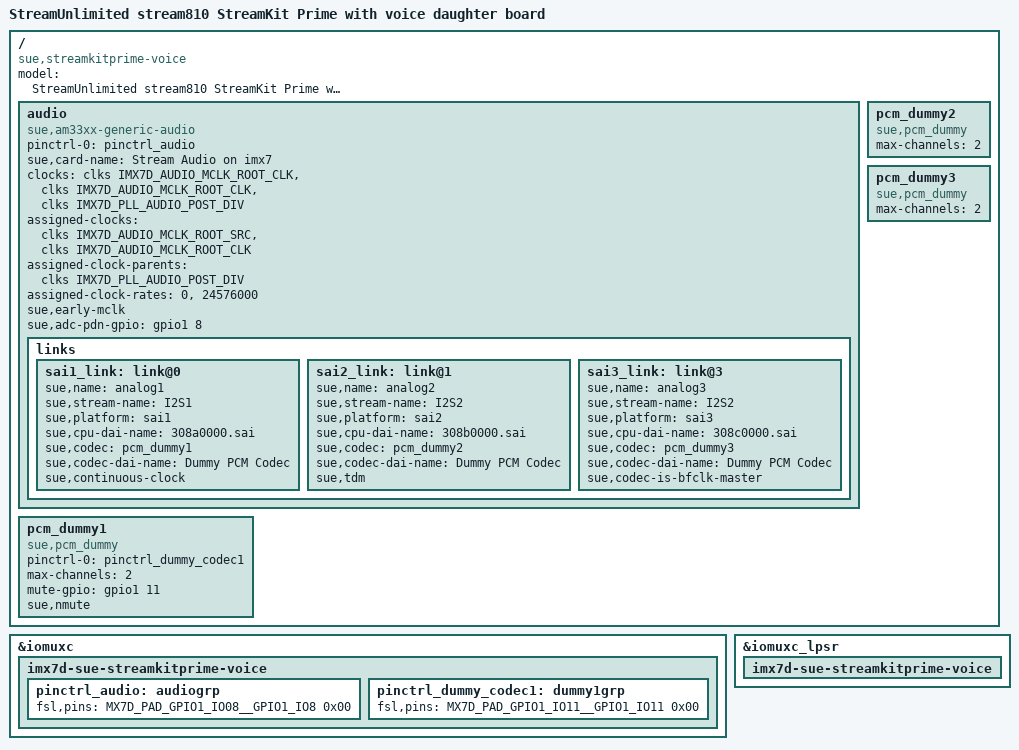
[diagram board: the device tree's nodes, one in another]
/*
 * This program is free software; you can redistribute it and/or modify
 * it under the terms of the GNU General Public License version 2 as
 * published by the Free Software Foundation.
 */

#include <dt-bindings/input/input.h>

/ {
	model = "StreamUnlimited stream810 StreamKit Prime with voice daughter board";
	compatible = "sue,streamkitprime-voice", "sue,streamkitprime", "sue,stream810", "fsl,imx7d";

	audio {
		pinctrl-names = "default";
		pinctrl-0 = <&pinctrl_audio>;

		compatible = "sue,am33xx-generic-audio";
		sue,card-name = "Stream Audio on imx7";

		clocks = <&clks IMX7D_AUDIO_MCLK_ROOT_CLK>,
			 <&clks IMX7D_AUDIO_MCLK_ROOT_CLK>,
			 <&clks IMX7D_PLL_AUDIO_POST_DIV>;
		clock-names = "mclk", "mclk_rx", "pll";

		assigned-clocks = <&clks IMX7D_AUDIO_MCLK_ROOT_SRC>,
				  <&clks IMX7D_AUDIO_MCLK_ROOT_CLK>;
		assigned-clock-parents = <&clks IMX7D_PLL_AUDIO_POST_DIV>;
		assigned-clock-rates = <0>, <24576000>;

		sue,early-mclk;

		sue,adc-pdn-gpio = <&gpio1 8 0>;

		links {
			sai1_link: link@0 {
				sue,name = "analog1";
				sue,stream-name = "I2S1";

				sue,platform = <&sai1>;
				sue,cpu-dai-name = "308a0000.sai";
				sue,codec = <&pcm_dummy1>;
				sue,codec-dai-name = "Dummy PCM Codec";
				sue,continuous-clock;
			};

			sai2_link: link@1 {
				sue,name = "analog2";
				sue,stream-name = "I2S2";

				sue,platform = <&sai2>;
				sue,cpu-dai-name = "308b0000.sai";
				sue,codec = <&pcm_dummy2>;
				sue,codec-dai-name = "Dummy PCM Codec";

				sue,tdm;
			};

			sai3_link: link@3 {
				sue,name = "analog3";
				sue,stream-name = "I2S2";

				sue,platform = <&sai3>;
				sue,cpu-dai-name = "308c0000.sai";
				sue,codec = <&pcm_dummy3>;
				sue,codec-dai-name = "Dummy PCM Codec";

				sue,codec-is-bfclk-master;
			};
		};
	};

	pcm_dummy1: pcm_dummy1 {
		pinctrl-names = "default";
		pinctrl-0 = <&pinctrl_dummy_codec1>;
		max-channels = <2>;

		compatible = "sue,pcm_dummy";
		mute-gpio = <&gpio1 11 0>;
		sue,nmute;
	};

	pcm_dummy2: pcm_dummy2 {
		compatible = "sue,pcm_dummy";
		max-channels = <2>;
	};

	pcm_dummy3: pcm_dummy3 {
		compatible = "sue,pcm_dummy";
		max-channels = <2>;
	};
};

/*
 * NOTES for the last number in every line:
 * 	PAD_CTL_PUS_100K_DOWN	(0 << 5)
 * 	PAD_CTL_PUS_5K_UP	(1 << 5)
 * 	PAD_CTL_PUS_47K_UP	(2 << 5)
 * 	PAD_CTL_PUS_100K_UP	(3 << 5)
 * 	PAD_CTL_PUE		(1 << 4)
 * 	PAD_CTL_HYS		(1 << 3)
 * 	PAD_CTL_SRE_SLOW	(1 << 2)
 * 	PAD_CTL_SRE_FAST	(0 << 2)
 * 	PAD_CTL_DSE_X1		(0 << 0) \
 * 	PAD_CTL_DSE_X2		(2 << 0)  |___ NOTE: the numbering here is not a typo!
 * 	PAD_CTL_DSE_X4		(1 << 0)  |
 * 	PAD_CTL_DSE_X6		(3 << 0) /
 * 	NO_PAD_CTL		(1 << 31): indicate this pin does not need config.
 * 	SIO			(1 << 30): Software Input On Field.
 */
&iomuxc {
	imx7d-sue-streamkitprime-voice {
		pinctrl_audio: audiogrp {
			fsl,pins = <
				MX7D_PAD_GPIO1_IO08__GPIO1_IO8		0x00    /* PDOWN_N */
			>;
		};

		pinctrl_dummy_codec1: dummy1grp {
			fsl,pins = <
				MX7D_PAD_GPIO1_IO11__GPIO1_IO11		0x00	/* NMUTE */
			>;
		};
	};
};

&iomuxc_lpsr {
	imx7d-sue-streamkitprime-voice {
	};
};
